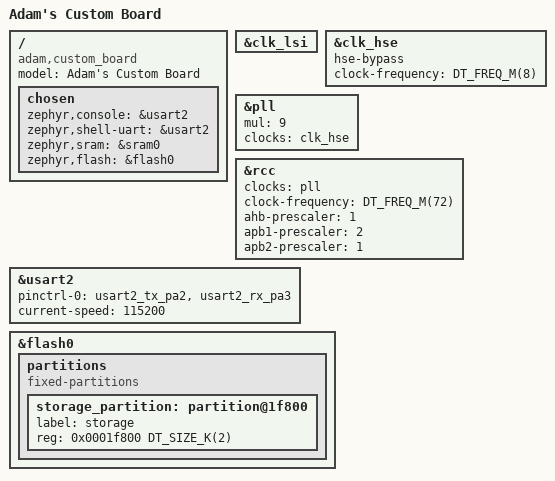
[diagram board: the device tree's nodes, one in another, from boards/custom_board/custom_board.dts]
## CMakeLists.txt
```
# SPDX-License-Identifier: Apache-2.0

cmake_minimum_required(VERSION 3.20.0)

find_package(Zephyr REQUIRED HINTS $ENV{ZEPHYR_BASE})
project(hello_world)

target_sources(app PRIVATE src/main.c)

add_subdirectory(drivers/led_driver)
```

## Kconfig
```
source "Kconfig.zephyr"
rsource "drivers/led_driver/Kconfig"
```

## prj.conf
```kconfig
CONFIG_LOG=y

CONFIG_GPIO=y

CONFIG_LED_DRIVER=y

CONFIG_SHELL=y
CONFIG_SHELL_CMDS=y
CONFIG_SHELL_TAB=y
CONFIG_SHELL_TAB_AUTOCOMPLETION=y
CONFIG_SHELL_HISTORY=y
CONFIG_SHELL_LOG_BACKEND=y
```

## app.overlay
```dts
/ {
    led_driver0: led_driver {
        compatible = "adam,led_driver";
        gpios = <&gpio0 0 GPIO_ACTIVE_HIGH>;
        status = "okay";
    };
};
```

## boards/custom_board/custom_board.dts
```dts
/dts-v1/;
#include <st/f1/stm32f103Xb.dtsi>
#include <st/f1/stm32f103r(8-b)tx-pinctrl.dtsi>
#include <zephyr/dt-bindings/input/input-event-codes.h>

/ {
	model = "Adam's Custom Board";
    compatible = "adam,custom_board";

	chosen {
        zephyr,console = &usart2;
		zephyr,shell-uart = &usart2;
		zephyr,sram = &sram0;
		zephyr,flash = &flash0;
	};
};

&clk_lsi {
	status = "okay";
};

&clk_hse {
	hse-bypass;
	clock-frequency = <DT_FREQ_M(8)>;
	status = "okay";
};

&pll {
	mul = <9>;
	clocks = <&clk_hse>;
	status = "okay";
};

&rcc {
	clocks = <&pll>;
	clock-frequency = <DT_FREQ_M(72)>;
	ahb-prescaler = <1>;
	apb1-prescaler = <2>;
	apb2-prescaler = <1>;
};

&usart2 {
	pinctrl-0 = <&usart2_tx_pa2 &usart2_rx_pa3>;
	pinctrl-names = "default";
	current-speed = <115200>;
	status = "okay";
};

&flash0 {
	partitions {
		compatible = "fixed-partitions";
		#address-cells = <1>;
		#size-cells = <1>;

		/* Set 2KB of storage at the end of 128KB flash */
		storage_partition: partition@1f800 {
			label = "storage";
			reg = <0x0001f800 DT_SIZE_K(2)>;
		};
	};
};
```

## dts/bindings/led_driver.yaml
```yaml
description: Simple LED driver
compatible: adam,led_driver
include: base.yaml

properties:
  gpios:
    type: phandle-array
    required: true
    description: GPIO for the on-board LED
```

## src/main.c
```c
/*
 * Copyright (c) 2012-2014 Wind River Systems, Inc.
 *
 * SPDX-License-Identifier: Apache-2.0
 */

#include <stdio.h>
#include <zephyr/kernel.h>
#include <zephyr/device.h>
#include <zephyr/devicetree.h>
#include <zephyr/drivers/sensor.h>
#include <zephyr/logging/log.h>
#include <zephyr/shell/shell.h>

LOG_MODULE_REGISTER(main, LOG_LEVEL_DBG);

const struct device *dev = DEVICE_DT_GET(DT_NODELABEL(led_driver0)); 

static int cmd_version(const struct shell *sh, size_t argc, char **argv)
{
	shell_print(sh, "Version is 1.0.0");
	return 0;
}

static int cmd_fetch(const struct shell *sh, size_t argc, char **argv)
{
	return sensor_sample_fetch(dev);
}

static int cmd_read(const struct shell *sh, size_t argc, char **argv)
{
    struct sensor_value value = {0};
	int ret = sensor_channel_get(dev, SENSOR_CHAN_AMBIENT_TEMP, &value);
	shell_print(sh, "Value = %d", value.val1);
	return ret;
}	

static int cmd_info(const struct shell *sh, size_t argc, char **argv)
{
	shell_print(sh, "Device name: %s", dev->name);
	shell_print(sh, "Device ready: %s", dev->state->initialized ? "Yes" : "No");
	return 0;
}

static int sub_cmd_set(const struct shell *sh, size_t argc, char **argv)
{
	if (argc != 2)
	{
		shell_error(sh, "Invalid number of subcommand arguments, expecting 1");
		return -EINVAL;
	}

	struct sensor_value value = {0};
	value.val1 = strtol(argv[1], NULL, 10);

	if (value.val1 == 0)
	{
		shell_error(sh, "Invalid value argument format");
		return -EINVAL;
	}

	return sensor_attr_set(dev, SENSOR_CHAN_ALL, SENSOR_ATTR_RESOLUTION, &value);
}

SHELL_CMD_REGISTER(version, NULL, "Print application version", cmd_version);
SHELL_CMD_REGISTER(fetch, NULL, "Fetch sensor sample", cmd_fetch);
SHELL_CMD_REGISTER(read, NULL, "Read sensor channel value", cmd_read);
SHELL_CMD_REGISTER(info, NULL, "Print device information and ready state", cmd_info);

SHELL_STATIC_SUBCMD_SET_CREATE(sensor_subcmds, 
	SHELL_CMD(set, NULL, "Set sensor attribute value", sub_cmd_set),
	SHELL_SUBCMD_SET_END
);
SHELL_CMD_ARG_REGISTER(sensor, &sensor_subcmds, "Sensor commands", NULL, 2, 0);

int main(void)
{
	while(1)
	{
		k_sleep(K_FOREVER);
	}

	return 0;
}
```
